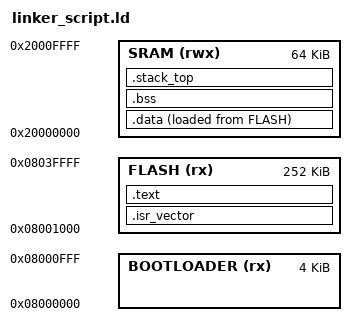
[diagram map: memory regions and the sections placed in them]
ENTRY(reset_handler)


/*linker script is a configuration file which instructs linker to combine object 
files into executable 
file , by controlling the memory layout of a program
this helps us to be specific about the requirements of a system
*/

MEMORY
{
/*  name Attribute) : orign = start address , lenght = length of the regions
    the name can be anything , can even be rajat
	// this name will be referenced by other parts of the linker script
	//rx means read only and code executable section
	//w means write only 
	//r means read only 
	//x means code executable region*/
	BOOTLOADER(rx):ORIGIN = 0x08000000,LENGTH = 4K
	FLASH (rx): ORIGIN = ORIGIN(BOOTLOADER)+LENGTH(BOOTLOADER),LENGTH = 256K-LENGTH(BOOTLOADER) 
	SRAM (rwx): ORIGIN = 0x20000000,LENGTH = 64K
}

PROVIDE(_estack = ORIGIN(SRAM) + LENGTH(SRAM));
/*relocation happens in startup code using symbols generated by linker script
to generate different output sections in the elf file  and also decides in 
which order the different regions appear in the elf file
*/
SECTIONS 

{
	.isr_vector :
	{
	  . = ORIGIN(FLASH); 
	  _stext = .;
	  KEEP(*(.isr_vector))
	  . = ALIGN(4);      
	}>FLASH
	
	.text :
	{
		. = ALIGN(4);
        
		*(.text)
		*(.rodata)

		. = ALIGN(4);

		_etext = .;

	}>FLASH
     /* dot(.) is a location counter , because linker updates the location//address
	  info automatically*/
	 
 	.data :
	{
		. = ALIGN(4);

		_sdata = .;

		*(.data)  /* this line will take all the .data sectoins from the .o files and linker will make sure to put all the .data section in the SRAM memory 
		//however , we would stil need to copy the .data from flash to ram at reset reset_handler
//the absolute address will be at SRAM , which is denoted by >SRAM and inital address will be at FLASH which is denoted by AT> FLASH 

(vma) > AT > (lma)  : virtual memory address and load memory address*/
		. = ALIGN(4);

		_edata = .;
	}>SRAM AT >FLASH /* will be intially placed in flash but finally copied or
	 placed in SRAM hence >SRAM AT>FLASH*/

	.bss :
	{
		. = ALIGN(4);
		_sbss = .;

		*(.bss)

		. = ALIGN(4);

		_ebss = .;
		
	}>SRAM

	    /* Define the end of stack (top address of SRAM) */
    .stack_top (NOLOAD): /* NOLOAD means it won't take space in the output binary */
    {
        . = ALIGN(8); 
        _estack = ORIGIN(SRAM) + LENGTH(SRAM); 
    } >SRAM

}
